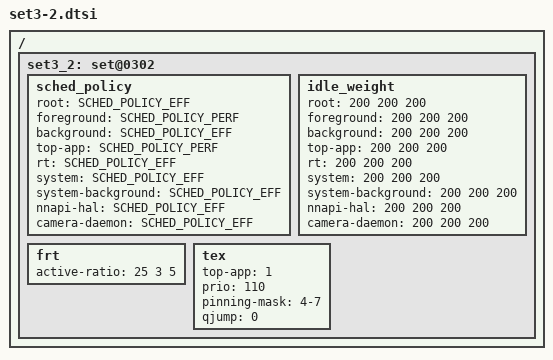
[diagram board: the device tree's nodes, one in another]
/ {
	/* game mode - app boost */
	set3_2: set@0302{
		/* schedudling policy */
		sched_policy {
			root			= <SCHED_POLICY_EFF>;
			foreground 		= <SCHED_POLICY_PERF>;
			background		= <SCHED_POLICY_EFF>;
			top-app			= <SCHED_POLICY_PERF>;
			rt			= <SCHED_POLICY_EFF>;
			system			= <SCHED_POLICY_EFF>;
			system-background	= <SCHED_POLICY_EFF>;
			nnapi-hal		= <SCHED_POLICY_EFF>;
			camera-daemon		= <SCHED_POLICY_EFF>;
		};

		/* weight (%) applied to idle cpu's efficiency */
		idle_weight {	   		/* LIT MEDBIG */
			root            	= <200 200 200>;
			foreground      	= <200 200 200>;
			background      	= <200 200 200>;
			top-app         	= <200 200 200>;
			rt			= <200 200 200>;
			system			= <200 200 200>;
			system-background	= <200 200 200>;
			nnapi-hal		= <200 200 200>;
			camera-daemon		= <200 200 200>;
		};

		frt {	   			/* LIT MED BIG */
			active-ratio 		= < 25   3   5>;
		};

		tex {
			top-app		= <1>;
			prio		= <110>;

			pinning-mask	= "4-7";
			qjump		= <0>;
		};
	};
};
